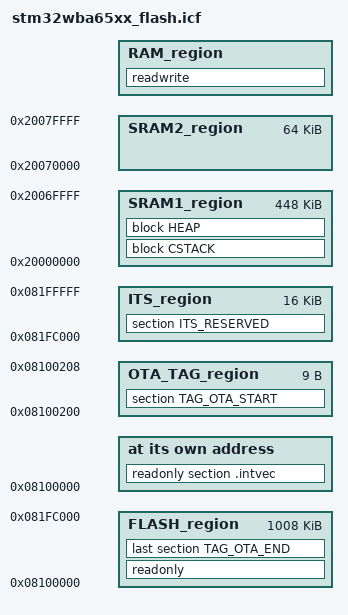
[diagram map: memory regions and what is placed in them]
/**********************************************************************************/
/**** Linker File (ICF)                                                        ****/
/**********************************************************************************/

/*-Series memory map-*/
define symbol __FLASH_BASE__              = 0x08000000;
define symbol __FLASH_TOP__               = 0x081FFFFF;
define symbol __SRAM1_BASE__              = 0x20000000;
define symbol __SRAM1_TOP__               = 0x2006FFFF;
define symbol __SRAM2_BASE__              = 0x20070000;
define symbol __SRAM2_TOP__               = 0x2007FFFF;

/*-Flash layout-*/
define symbol __region_FLASH_start__      = 0x08100000;
define symbol __region_FLASH_end__        = __FLASH_TOP__;
define symbol __region_ITS_size__         = 0x4000;
define symbol __region_ITS_end__          = __FLASH_TOP__;
define symbol __region_ITS_start__        = __region_ITS_end__ - __region_ITS_size__ + 0x1;

/*-Exported symbols-*/
define exported symbol __its_start__ = __region_ITS_start__;

/*-RAM layout-*/
define symbol __region_SRAM1_start__      = __SRAM1_BASE__;
define symbol __region_SRAM1_end__        = __SRAM1_TOP__;
define symbol __region_SRAM2_start__      = __SRAM2_BASE__;
define symbol __region_SRAM2_end__        = __SRAM2_TOP__;

/*-Stack and heap-*/
define symbol __ICFEDIT_size_heap__   = 0x1200;
define symbol __ICFEDIT_size_cstack__ = 0x1000;
define symbol __intvec_start__            = __region_FLASH_start__;

/*-Regions-*/
define memory mem with size = 4G;
define region ITS_region        = mem:[from __region_ITS_start__ to __region_ITS_end__];
define region FLASH_region      = mem:[from __region_FLASH_start__ to __region_ITS_start__];
define region SRAM1_region      = mem:[from __region_SRAM1_start__ to __region_SRAM1_end__];
define region SRAM2_region      = mem:[from __region_SRAM2_start__ to __region_SRAM2_end__];
define region RAM_region        = SRAM1_region | SRAM2_region;
define region OTA_TAG_region    = mem:[from (__region_FLASH_start__ + 0x200) to (__region_FLASH_start__ + 0x200 + 0x8)];

/*-Blocks-*/
define block HEAP   with alignment = 8, size = __ICFEDIT_size_heap__   { };
define block CSTACK with alignment = 8, size = __ICFEDIT_size_cstack__ { };

/*-Initialization strategies-*/
initialize by copy { readwrite };
do not initialize  { section .noinit };

/*-Sections placements-*/
place at address mem:__intvec_start__ { readonly section .intvec };
keep                        { section TAG_OTA_START };
keep                        { section TAG_OTA_END };
place in ITS_region         { section ITS_RESERVED };
place in OTA_TAG_region     { section TAG_OTA_START };
place in FLASH_region       { readonly, last section TAG_OTA_END };
place in SRAM1_region       { block CSTACK, block HEAP };
place in SRAM2_region       { };
place in RAM_region         { readwrite };
